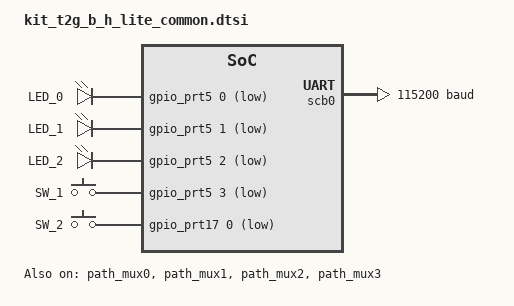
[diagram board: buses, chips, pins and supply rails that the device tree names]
/*
 * Copyright (c) 2025 Infineon Technologies AG,
 * or an affiliate of Infineon Technologies AG.
 *
 * SPDX-License-Identifier: Apache-2.0
 */

#include <arm/infineon/cat1c/xmc7200/system_clocks.dtsi>
#include <arm/infineon/cat1c/mpns/cyt4bf8cds.dtsi>
#include <zephyr/dt-bindings/input/input-event-codes.h>

/ {
	aliases {
		led0 = &user_led0;
		led1 = &user_led1;
		led2 = &user_led2;
		sw0 = &user_bt0;
		sw1 = &user_bt1;
	};

	leds {
		compatible = "gpio-leds";

		user_led0: led_0 {
			label = "LED_0";
			gpios = <&gpio_prt5 0 GPIO_ACTIVE_LOW>;
		};

		user_led1: led_1 {
			label = "LED_1";
			gpios = <&gpio_prt5 1 GPIO_ACTIVE_LOW>;
		};

		user_led2: led_2 {
			label = "LED_2";
			gpios = <&gpio_prt5 2 GPIO_ACTIVE_LOW>;
		};
	};

	gpio_keys {
		compatible = "gpio-keys";

		user_bt0: user_btn0 {
			label = "SW_1";
			gpios = <&gpio_prt5 3 (GPIO_PULL_UP | GPIO_ACTIVE_LOW)>;
			zephyr,code = <INPUT_KEY_0>;
		};

		user_bt1: user_btn1 {
			label = "SW_2";
			gpios = <&gpio_prt17 0 (GPIO_PULL_UP | GPIO_ACTIVE_LOW)>;
			zephyr,code = <INPUT_KEY_1>;
		};
	};
};

uart0: &scb0 {
	compatible = "infineon,cat1-uart";
	status = "okay";
	current-speed = <115200>;

	/* UART pins */
	pinctrl-0 = <&p0_1_scb0_uart_tx &p0_0_scb0_uart_rx
		     &p0_2_scb0_uart_rts &p0_3_scb0_uart_cts>;
	pinctrl-names = "default";
};

&gpio_prt5 {
	status = "okay";
};

&gpio_prt17 {
	status = "okay";
};

&path_mux0 {
	status = "okay";
};

&path_mux1 {
	status = "okay";
};

&path_mux2 {
	status = "okay";
};

&path_mux3 {
	status = "okay";
};

&clk_mem {
	status = "okay";
};

&clk_peri {
	status = "okay";
};

&clk_slow {
	status = "okay";
};
